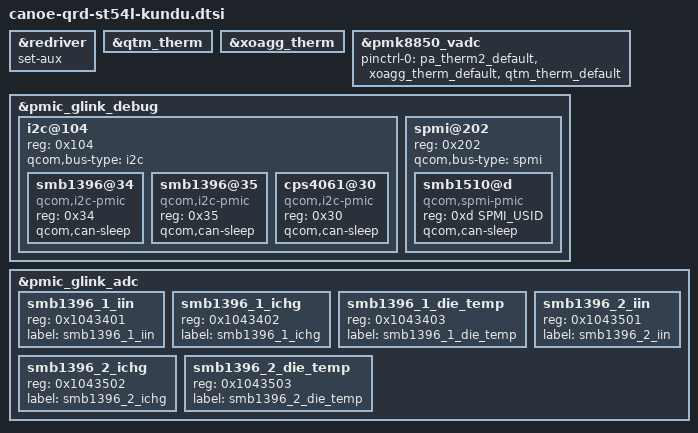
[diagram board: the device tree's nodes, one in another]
// SPDX-License-Identifier: BSD-3-Clause
/*
 * Copyright (c) 2024-2025 Qualcomm Innovation Center, Inc. All rights reserved.
 */

#include <dt-bindings/spmi/spmi.h>

#include "canoe-qrd.dtsi"

&redriver {
	set-aux;
};

&qtm_therm {
	status = "ok";
};

&xoagg_therm {
	status = "ok";
};

&pmk8850_vadc {
	pinctrl-0 = <&pa_therm2_default>, <&xoagg_therm_default>, <&qtm_therm_default>;
	pinctrl-names = "default";
};

&pmic_glink_debug {
	i2c@104 {
		reg = <0x104>; /* I2C instance 4 in ADSP for SE3 */
		#address-cells = <1>;
		#size-cells = <0>;
		qcom,bus-type = "i2c";

		smb1396@34 {
			compatible = "qcom,i2c-pmic";
			reg = <0x34>;
			qcom,can-sleep;
		};

		smb1396@35 {
			compatible = "qcom,i2c-pmic";
			reg = <0x35>;
			qcom,can-sleep;
		};

		cps4061@30 {
			compatible = "qcom,i2c-pmic";
			reg = <0x30>;
			qcom,can-sleep;
		};
	};

	/* SPMI bridge bus 2 with SMB1510 device */
	spmi@202 {
		reg = <0x202>;
		#address-cells = <2>;
		#size-cells = <0>;
		qcom,bus-type = "spmi";

		smb1510@d {
			compatible = "qcom,spmi-pmic";
			reg = <0xd SPMI_USID>;
			qcom,can-sleep;
		};
	};
};

&pmic_glink_adc {
	status = "ok";

	smb1396_1_iin {
		reg = <0x1043401>;
		label = "smb1396_1_iin";
	};

	smb1396_1_ichg {
		reg = <0x1043402>;
		label = "smb1396_1_ichg";
	};

	smb1396_1_die_temp {
		reg = <0x1043403>;
		label = "smb1396_1_die_temp";
	};

	smb1396_2_iin {
		reg = <0x1043501>;
		label = "smb1396_2_iin";
	};

	smb1396_2_ichg {
		reg = <0x1043502>;
		label = "smb1396_2_ichg";
	};

	smb1396_2_die_temp {
		reg = <0x1043503>;
		label = "smb1396_2_die_temp";
	};
};
